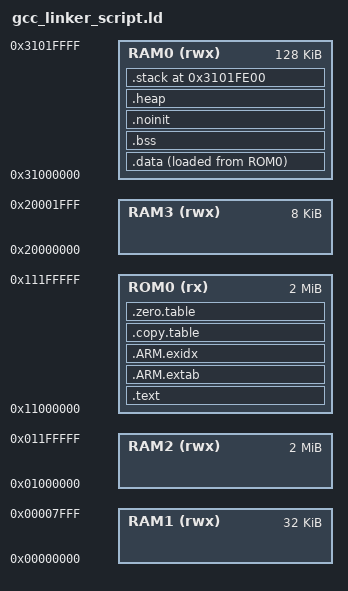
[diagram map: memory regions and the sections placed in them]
MEMORY
{
  ROM0 (rx) : ORIGIN = 0x11000000, LENGTH = 0x00200000
  RAM0 (rwx) : ORIGIN = 0x31000000, LENGTH = 0x00020000
  RAM1 (rwx) : ORIGIN = 0x00000000, LENGTH = 0x00008000
  RAM2 (rwx) : ORIGIN = 0x01000000, LENGTH = 0x00200000
  RAM3 (rwx) : ORIGIN = 0x20000000, LENGTH = 0x00002000
}
ENTRY(Reset_Handler)
SECTIONS
{
  .text :
  {
    KEEP(*(.vectors))
    *(.text*)
    KEEP(*(.init))
    KEEP(*(.fini))
    *crtbegin.o(.ctors)
    *crtbegin?.o(.ctors)
    *(EXCLUDE_FILE(*crtend?.o *crtend.o) .ctors)
    *(SORT(.ctors.*))
    *(.ctors)
    *crtbegin.o(.dtors)
    *crtbegin?.o(.dtors)
    *(EXCLUDE_FILE(*crtend?.o *crtend.o) .dtors)
    *(SORT(.dtors.*))
    *(.dtors)
    *(.rodata*)
    KEEP(*(.eh_frame*))
  } > ROM0
  .ARM.extab :
  {
    *(.ARM.extab* .gnu.linkonce.armextab.*)
  } > ROM0
  __exidx_start = .;
  .ARM.exidx :
  {
    *(.ARM.exidx* .gnu.linkonce.armexidx.*)
  } > ROM0
  __exidx_end = .;
  .copy.table :
  {
    . = ALIGN(4);
    __copy_table_start__ = .;
    LONG (LOADADDR(.data))
    LONG (ADDR(.data))
    LONG (SIZEOF(.data) / 4)
    __copy_table_end__ = .;
  } > ROM0
  .zero.table :
  {
    . = ALIGN(4);
    __zero_table_start__ = .;
    __zero_table_end__ = .;
  } > ROM0
  PROVIDE(__etext = LOADADDR(.data));
  .data : ALIGN(4)
  {
    __data_start__ = .;
    *(vtable)
    *(.data)
    *(.data.*)
    . = ALIGN(4);
    PROVIDE_HIDDEN (__preinit_array_start = .);
    KEEP(*(.preinit_array))
    PROVIDE_HIDDEN (__preinit_array_end = .);
    . = ALIGN(4);
    PROVIDE_HIDDEN (__init_array_start = .);
    KEEP(*(SORT(.init_array.*)))
    KEEP(*(.init_array))
    PROVIDE_HIDDEN (__init_array_end = .);
    . = ALIGN(4);
    PROVIDE_HIDDEN (__fini_array_start = .);
    KEEP(*(SORT(.fini_array.*)))
    KEEP(*(.fini_array))
    PROVIDE_HIDDEN (__fini_array_end = .);
    KEEP(*(.jcr*))
    . = ALIGN(4);
    __data_end__ = .;
  } > RAM0 AT > ROM0
  .bss :
  {
    . = ALIGN(4);
    __bss_start__ = .;
    *(.bss)
    *(.bss.*)
    *(COMMON)
    . = ALIGN(4);
    __bss_end__ = .;
  } > RAM0 AT > RAM0
  .noinit (NOLOAD) :
  {
    . = ALIGN(4);
    __noinit_start = .;
    *(.noinit)
    *(.noinit.*)
    . = ALIGN(4);
    __noinit_end = .;
  } > RAM0
  .heap (NOLOAD) :
  {
    . = ALIGN(8);
    __end__ = .;
    PROVIDE(end = .);
    . = . + 0x00000C00;
    . = ALIGN(8);
    __HeapLimit = .;
  } > RAM0
  .stack (ORIGIN(RAM0) + LENGTH(RAM0) - 0x00000200 - ( 0 )) (NOLOAD) :
  {
    . = ALIGN(8);
    __StackLimit = .;
    . = . + 0x00000200;
    . = ALIGN(8);
    __StackTop = .;
  } > RAM0
  PROVIDE(__stack = __StackTop);
  ASSERT(__StackLimit >= __HeapLimit, "region RAM overflowed with stack")
}
